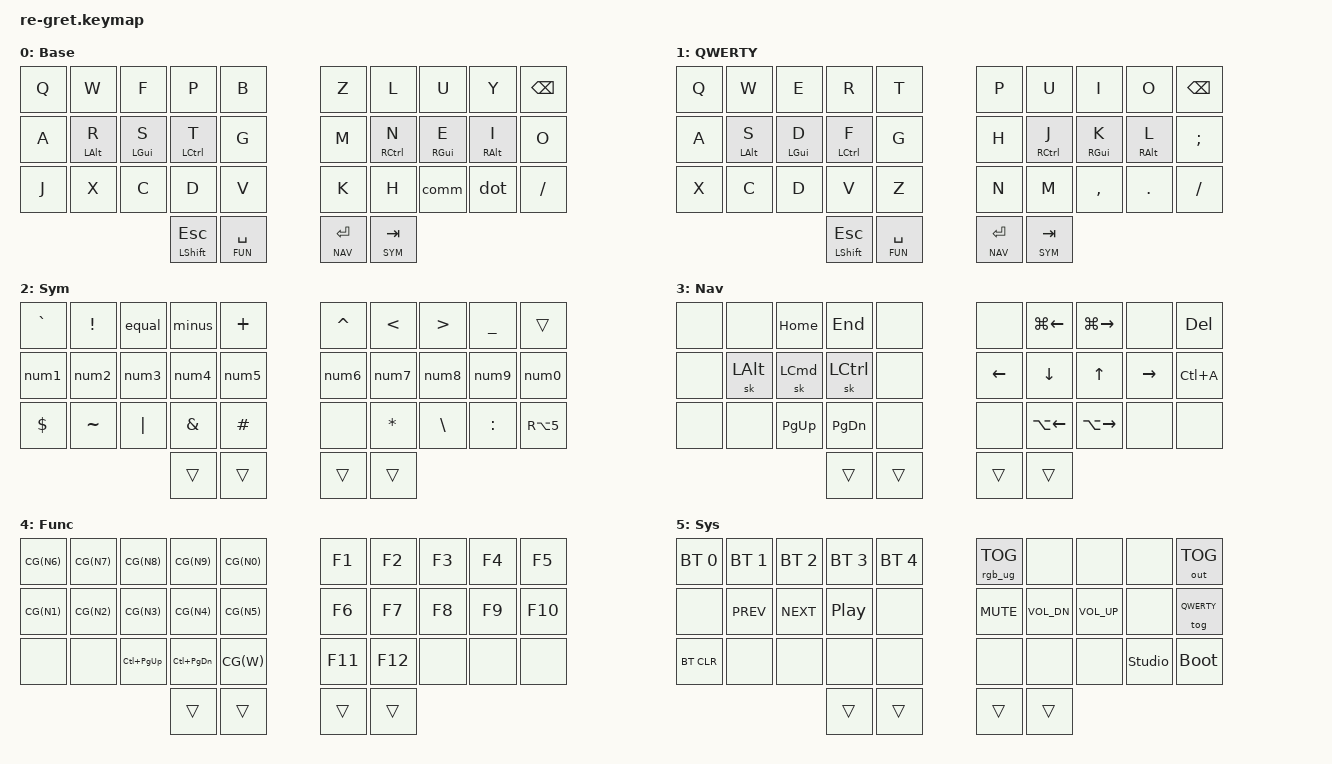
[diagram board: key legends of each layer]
#include <behaviors.dtsi>
#include <dt-bindings/zmk/keys.h>
#include <dt-bindings/zmk/rgb.h>
#include <dt-bindings/zmk/bt.h>
#include <dt-bindings/zmk/outputs.h>

#define TAPPING_TERM 200
#define TAPPING_IDLE 140
#define QUICK_TAP 200

#define COMBO_IDLE 50
#define COMBO_TERM 25

#define BASE 0
#define QWERTY 1
#define SYM 2
#define NAV 3
#define FUN 4
#define SYS 5

#define CG(x) LG(LC(x))

#define SHIFT_OVERRIDE(KEY1, KEY2) \
    override_##KEY1_##KEY2 { \
        compatible = "zmk,behavior-mod-morph";\
        #binding-cells = <0>;\
        bindings = <&kp KEY1>, <&kp KEY2>;\
        mods = <(MOD_LSFT)>;\
    }

#define NUM(KC, NUMBER) shift_morph_##KC_##NUMBER: SHIFT_OVERRIDE(KC, NUMBER)

#define LEFT_AND_THUMBS 0 1 2 3 4 10 11 12 13 14 20 21 22 23 24 30 31 32 33
#define RIGHT_AND_THUMBS 5 6 7 8 9 15 16 17 18 19 25 26 27 28 29 30 31 32 33


/ {
    behaviors {
        hml: homerow_mods_left {
            compatible = "zmk,behavior-hold-tap";
            #binding-cells = <2>;
            bindings = <&kp>, <&kp>;
            flavor = "balanced";
            tapping-term-ms = <TAPPING_TERM>;
            require-prior-idle-ms = <TAPPING_IDLE>;
            quick-tap-ms = <QUICK_TAP>;
            hold-trigger-on-release;
            hold-trigger-key-positions = <RIGHT_AND_THUMBS>;
        };
        hmr: homerow_mods_right {
            compatible = "zmk,behavior-hold-tap";
            #binding-cells = <2>;
            bindings = <&kp>, <&kp>;
            flavor = "balanced";
            tapping-term-ms = <TAPPING_TERM>;
            require-prior-idle-ms = <TAPPING_IDLE>;
            quick-tap-ms = <QUICK_TAP>;
            hold-trigger-on-release;
            hold-trigger-key-positions = <LEFT_AND_THUMBS>;
        };
        qmt: quick_mod_tap {
            compatible = "zmk,behavior-hold-tap";
            #binding-cells = <2>;
            flavor = "hold-preferred";
            bindings = <&kp>, <&kp>;
            tapping-term-ms = <TAPPING_TERM>;
            quick-tap-ms = <QUICK_TAP>;
            hold-trigger-on-release;
        };
        blt: balanced_layer_tap {
            compatible = "zmk,behavior-hold-tap";
            #binding-cells = <2>;
            bindings = <&mo>, <&kp>;
            flavor = "balanced";
            tapping-term-ms = <TAPPING_TERM>;
            require-prior-idle-ms = <TAPPING_IDLE>;
            quick-tap-ms = <QUICK_TAP>;
            hold-trigger-on-release;
        };
        qlt: quick_layer_tab {
            compatible = "zmk,behavior-hold-tap";
            #binding-cells = <2>;
            bindings = <&mo>, <&kp>;
            flavor = "hold-preferred";
            tapping-term-ms = <TAPPING_TERM>;
            quick-tap-ms = <QUICK_TAP>;
            hold-trigger-on-release;
        };
    };
 
    combos {
        compatible = "zmk,combos";
        // esc { key-positions = <22 23>; bindings = <&kp ESC>; require-prior-idle-ms = <COMBO_IDLE>; timeout-ms = <COMBO_TERM>;};
        // tab { key-positions = <26 27>; bindings = <&kp TAB>; require-prior-idle-ms = <COMBO_IDLE>; timeout-ms = <COMBO_TERM>;};
        ralt1 { key-positions = <22 23>; bindings = <&sk RIGHT_ALT>; require-prior-idle-ms = <COMBO_IDLE>; timeout-ms = <COMBO_TERM>; layers = <BASE QWERTY SYM>;};
        ralt2 { key-positions = <26 27>; bindings = <&sk RIGHT_ALT>; require-prior-idle-ms = <COMBO_IDLE>; timeout-ms = <COMBO_TERM>;layers = <BASE QWERTY SYM>;};
    };
     
    conditional_layers {
        compatible = "zmk,conditional-layers";
        sys_layer {
            if-layers = <NAV FUN>;
            then-layer = <SYS>;
        };
    };


    // Numbers 
    num1: SHIFT_OVERRIDE(SQT, N1);
    num2: SHIFT_OVERRIDE(LBKT, N2);
    num3: SHIFT_OVERRIDE(LBRC, N3);
    num4: SHIFT_OVERRIDE(LPAR, N4);
    num5: SHIFT_OVERRIDE(PRCNT, N5);
    num6: SHIFT_OVERRIDE(AT, N6);
    num7: SHIFT_OVERRIDE(RPAR, N7);
    num8: SHIFT_OVERRIDE(RBRC, N8);
    num9: SHIFT_OVERRIDE(RBKT, N9);
    num0: SHIFT_OVERRIDE(DQT, N0);

    comm: SHIFT_OVERRIDE(COMMA, SEMI);
    dot: SHIFT_OVERRIDE(DOT, COLON);

    minus: SHIFT_OVERRIDE(MINUS, MINUS);
    equal: SHIFT_OVERRIDE(EQUAL, EQUAL);


    
    keymap {
        compatible = "zmk,keymap";

        default_layer {
            display-name = "Base";
            bindings = <
                &kp Q      &kp W       &kp F       &kp P          &kp B          &kp Z          &kp L          &kp U       &kp Y       &kp BSPC
                &kp A      &hml LALT R &hml LGUI S &hml LCTRL T   &kp G          &kp M          &hmr RCTRL N   &hmr RGUI E &hmr RALT I &kp O
                &kp J      &kp X       &kp C       &kp D          &kp V          &kp K          &kp H          &comm       &dot        &kp FSLH
                                                   &qmt LSHFT ESC &blt FUN SPACE &qlt NAV RET   &qlt SYM TAB
            >;
        };
        qwerty_layer { // Not Really Finished
            display-name = "QWERTY";
            bindings = <
                &kp Q      &kp W       &kp E       &kp R          &kp T          &kp P          &kp U          &kp I       &kp O       &kp BSPC
                &kp A      &hml LALT S &hml LGUI D &hml LCTRL F   &kp G          &kp H          &hmr RCTRL J   &hmr RGUI K &hmr RALT L &kp SEMI
                &kp X      &kp C       &kp D       &kp V          &kp Z          &kp N          &kp M          &kp COMMA   &kp DOT     &kp FSLH
                                                   &qmt LSHFT ESC &blt FUN SPACE &qlt NAV RET   &qlt SYM TAB
            >;
        };
        sym_layer {
            display-name = "Sym";    
            bindings = <
                &kp GRAVE  &kp EXCL   &equal      &minus          &kp PLUS      &kp CARET       &kp LT         &kp GT      &kp UNDER  &trans   
                &num1      &num2      &num3       &num4           &num5         &num6           &num7          &num8       &num9      &num0    
                &kp DLLR   &kp TILDE  &kp PIPE    &kp AMPS        &kp HASH      &none           &kp STAR       &kp BSLH    &kp COLON  &kp RA(N5)
                                                  &trans          &trans        &trans          &trans
            >;
        };
        nav_layer {
            display-name = "Nav";
            bindings = <
                &none       &none       &kp HOME   &kp END        &none         &none           &kp LG(LEFT)   &kp LG(RIGHT)&none      &kp DEL 
                &none       &sk LALT    &sk LCMD   &sk LCTRL      &none         &kp LEFT        &kp DOWN       &kp UP       &kp RIGHT  &kp LC(A)
                &none       &none       &kp PG_UP  &kp PG_DN      &none         &none           &kp LA(LEFT)   &kp LA(RIGHT)&none      &none 
                                                   &trans         &trans        &trans          &trans
            >;
        };
        function_layer {
            display-name = "Func";
            bindings = <
                &kp CG(N6)    &kp CG(N7)   &kp CG(N8)   &kp CG(N9)    &kp CG(N0)    &kp F1    &kp F2        &kp F3       &kp F4       &kp F5   
                &kp CG(N1)    &kp CG(N2)   &kp CG(N3)   &kp CG(N4)    &kp CG(N5)    &kp F6    &kp F7        &kp F8       &kp F9       &kp F10      
                &none         &none        &kp LC(PG_UP)&kp LC(PG_DN) &kp CG(W)     &kp F11   &kp F12       &none        &none        &none 
                                                        &trans        &trans        &trans    &trans
            >;
        };
        system_layer {
            display-name = "Sys";
            bindings = <
                &bt BT_SEL 0 &bt BT_SEL 1   &bt BT_SEL 2 &bt BT_SEL 3   &bt BT_SEL 4  &rgb_ug RGB_TOG &none          &none        &none      &out OUT_TOG
                &none        &kp C_PREV     &kp C_NEXT   &kp C_PP       &none         &kp C_MUTE      &kp C_VOL_DN   &kp C_VOL_UP &none      &tog QWERTY
                &bt BT_CLR   &none          &none        &none          &none         &none           &none          &none        &studio_unlock &bootloader
                                                         &trans         &trans        &trans          &trans
            >;
        };
    };
};
